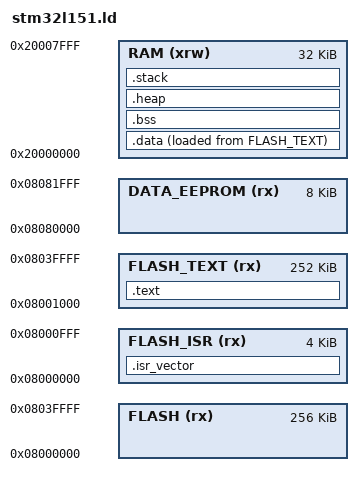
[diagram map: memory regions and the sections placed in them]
/*
*****************************************************************************
**
**  File        : STM32L151XC_FLASH.ld
**
**  Abstract    : Linker script for STM32L151XC Device with
**                256KByte FLASH, 32KByte RAM
**
**                Set heap size, stack size and stack location according
**                to application requirements.
**
**                Set memory bank area and size if external memory is used.
**
**  Target      : STMicroelectronics STM32
**
**  Environment : Atollic TrueSTUDIO(R)
**
**  Distribution: The file is distributed �as is,� without any warranty
**                of any kind.
**
**  (c)Copyright Atollic AB.
**  You may use this file as-is or modify it according to the needs of your
**  project. This file may only be built (assembled or compiled and linked)
**  using the Atollic TrueSTUDIO(R) product. The use of this file together
**  with other tools than Atollic TrueSTUDIO(R) is not permitted.
**
*****************************************************************************
*/

/* Entry Point */
ENTRY(Reset_Handler)

/* Highest address of the user mode stack */
_estack = 0x20007FFF;    /* end of RAM */

/* Generate a link error if heap and stack don't fit into RAM */
_Min_Heap_Size = 0x200;      /* required amount of heap  */
_Min_Stack_Size = 0x400; /* required amount of stack */

/* Specify the memory areas */
MEMORY
{
    FLASH (rx)      : ORIGIN = 0x08000000, LENGTH = 0x040000 /* Flash, 256 KB */
    FLASH_ISR (rx)  : ORIGIN = 0x08000000, LENGTH = 0x001000 /* sector 0, 4 KB */
    FLASH_TEXT (rx) : ORIGIN = 0x08001000, LENGTH = 0x03f000 /* sectors 1-63 = 252 KB */
    DATA_EEPROM (rx): ORIGIN = 0x08080000, LENGTH = 0x002000 /* Data EEPROM, 8KB */
    RAM (xrw)       : ORIGIN = 0x20000000, LENGTH = 0x008000 /* RAM, 32KB */
}

ENTRY(Reset_Handler)

/* produce a link error if there is not this amount of RAM for these sections */
_minimum_stack_size = 2K;
_minimum_heap_size = 16K;

/* Define tho top end of the stack.  The stack is full descending so begins just
   above last byte of RAM.  Note that EABI requires the stack to be 8-byte
   aligned for a call. */
_estack = ORIGIN(RAM) + LENGTH(RAM);

/* RAM extents for the garbage collector */
_ram_end = ORIGIN(RAM) + LENGTH(RAM);
_heap_end = 0x2001c000; /* tunable */

/* define output sections */
SECTIONS
{
    /* The startup code goes first into FLASH */
    .isr_vector :
    {
        . = ALIGN(4);
        KEEP(*(.isr_vector)) /* Startup code */
        . = ALIGN(4);
        /*
        /* This first flash block is 16K annd the isr vectors only take up
           about 400 bytes. So we pull in a couple of object files to pad it
           out. */

        . = ALIGN(4);
        */ff.o(.text*)
        */stm32l1xx_hal_sd.o(.text*)
        */
    } >FLASH_ISR

    /* The program code and other data goes into FLASH */
    .text :
    {
        . = ALIGN(4);
        *(.text*)          /* .text* sections (code) */
        *(.rodata*)        /* .rodata* sections (constants, strings, etc.) */
    /*  *(.glue_7)   */    /* glue arm to thumb code */
    /*  *(.glue_7t)  */    /* glue thumb to arm code */

        . = ALIGN(4);
        _etext = .;        /* define a global symbol at end of code */
    } >FLASH_TEXT

    /*
    .ARM.extab :
    {
        *(.ARM.extab* .gnu.linkonce.armextab.*)
    } >FLASH

    .ARM :
    {
        __exidx_start = .;
        *(.ARM.exidx*)
        __exidx_end = .;
    } >FLASH
    */

    /* used by the startup to initialize data */
    _sidata = LOADADDR(.data);

    /* This is the initialized data section
    The program executes knowing that the data is in the RAM
    but the loader puts the initial values in the FLASH (inidata).
    It is one task of the startup to copy the initial values from FLASH to RAM. */
    .data :
    {
        . = ALIGN(4);
        _sdata = .;        /* create a global symbol at data start; used by startup code in order to initialise the .data section in RAM */
        _ram_start = .;    /* create a global symbol at ram start for garbage collector */
        *(.data*)          /* .data* sections */

        . = ALIGN(4);
        _edata = .;        /* define a global symbol at data end; used by startup code in order to initialise the .data section in RAM */
    } >RAM AT> FLASH_TEXT

    /* Uninitialized data section */
    .bss :
    {
        . = ALIGN(4);
        _sbss = .;         /* define a global symbol at bss start; used by startup code */
        *(.bss*)
        *(COMMON)

        . = ALIGN(4);
        _ebss = .;         /* define a global symbol at bss end; used by startup code and GC */
    } >RAM

    /* this is to define the start of the heap, and make sure we have a minimum size */
    .heap :
    {
        . = ALIGN(4);
	PROVIDE ( end = . );
	PROVIDE ( _end = . );
        _heap_start = .;    /* define a global symbol at heap start */
        . = . + _minimum_heap_size;
    } >RAM

    /* this just checks there is enough RAM for the stack */
    .stack :
    {
        . = ALIGN(4);
        . = . + _minimum_stack_size;
        . = ALIGN(4);
    } >RAM

    /* Remove information from the standard libraries */
    /*
    /DISCARD/ :
    {
        libc.a ( * )
        libm.a ( * )
        libgcc.a ( * )
    }
    */

    .ARM.attributes 0 : { *(.ARM.attributes) }
}
